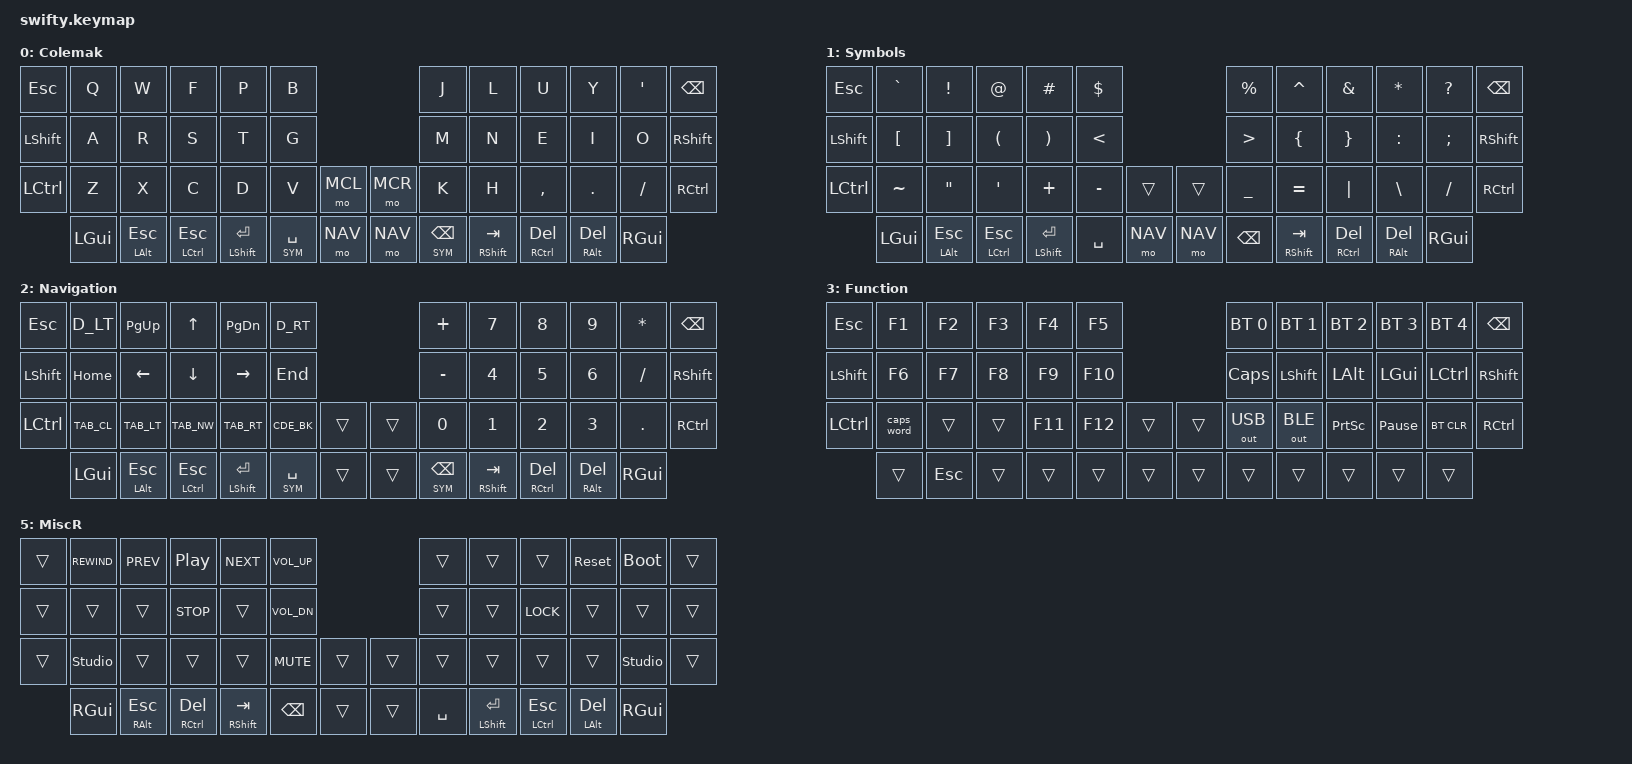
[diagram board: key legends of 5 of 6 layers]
#include <behaviors.dtsi>
#include <dt-bindings/zmk/keys.h>
#include <dt-bindings/zmk/bt.h>
#include <dt-bindings/zmk/outputs.h>
#include <dt-bindings/zmk/rgb.h>
#include <dt-bindings/zmk/rgb_colors.h>
#include <dt-bindings/zmk/hid_indicators.h>

// Layer aliases
#define CMK  0
#define SYM  1
#define NAV  2
#define FUN  3
#define MCL  4
#define MCR  5

// Desktop keycodes
#define D_LT   LC(LA(LEFT))
#define D_RT   LC(LA(RIGHT))

// Browser keycodes
#define TAB_NW LC(T)
#define TAB_RT LC(TAB)
#define TAB_LT LC(LS(TAB))
#define TAB_CL LC(W)

// VS Code keycodes
#define CDE_BK LC(LA(MINUS))
#define CDE_FD LC(LS(MINUS))

&caps_word {
    continue-list = <UNDERSCORE MINUS BSPC DEL N1 N2 N3 N4 N5 N6 N7 N8 N9 N0>;
};


/ {
    behaviors {
          ltr: layer_toggle_right {
               compatible = "zmk,behavior-hold-tap";
               display-name = "LT Right";
               #binding-cells = <2>;
               flavor = "hold-preferred";
               tapping-term-ms = <200>;
               bindings = <&mo>, <&kp>;
          };
          ltl: layer_toggle_left {
               compatible = "zmk,behavior-hold-tap";
               display-name = "LT Left";
               #binding-cells = <2>;
               flavor = "hold-preferred";
               tapping-term-ms = <200>;
               bindings = <&mo>, <&kp>;
          };
    };

    cond_layers {
        compatible = "zmk,conditional-layers";
        // Define FUN layer as tri-state
        navsym {
            if-layers = <NAV SYM>;
            then-layer = <FUN>;
        };
    };

    keymap {
       compatible = "zmk,keymap";
       Colemak_layer {
          display-name = "Colemak";
          bindings = <

// ╭─────────────┬─────────────┬─────────────┬─────────────┬─────────────┬─────────────╮                               ╭─────────────┬─────────────┬─────────────┬─────────────┬─────────────┬─────────────╮
     &kp ESC       &kp Q         &kp W         &kp F         &kp P         &kp B                                         &kp J         &kp L         &kp U         &kp Y         &kp SQT       &kp BSPC
// ├─────────────┼─────────────┼─────────────┼─────────────┼─────────────┼─────────────┤                               ├─────────────┼─────────────┼─────────────┼─────────────┼─────────────┼─────────────┤
     &kp LSHFT     &kp A         &kp R         &kp S         &kp T         &kp G                                         &kp M         &kp N         &kp E         &kp I         &kp O         &kp RSHFT
// ├─────────────┼─────────────┼─────────────┼─────────────┼─────────────┼─────────────┤─────────────╮   ╭─────────────├─────────────┼─────────────┼─────────────┼─────────────┼─────────────┼─────────────┤
     &kp LCTRL     &kp Z         &kp X         &kp C         &kp D         &kp V         &mo MCL           &mo MCR       &kp K         &kp H         &kp COMMA     &kp DOT       &kp SLASH     &kp RCTRL
// ╰─────────────┼─────────────┼─────────────┼─────────────┼─────────────┼─────────────┼─────────────┤   ┼─────────────├─────────────┼─────────────┼─────────────┼─────────────┴─────────────┴─────────────╯
                   &kp LGUI      &mt LALT ESC  &mt LCTRL ESC &mt LSHFT RET &ltr SYM SPACE &mo NAV          &mo NAV       &ltl SYM BSPC &mt RSHFT TAB &mt RCTRL DEL  &mt RALT DEL  &kp RGUI
//               ╰─────────────┴─────────────┴─────────────┴─────────────┴─────────────┴─────────────╯   ╰─────────────┴─────────────┴─────────────┴─────────────┴─────────────┴─────────────╯
        >;

     };
     Symbols_layer { 
          display-name = "Symbols";
          bindings = <
// ╭─────────────┬─────────────┬─────────────┬─────────────┬─────────────┬─────────────╮                               ╭─────────────┬─────────────┬─────────────┬─────────────┬─────────────┬─────────────╮
     &kp ESC       &kp GRAVE     &kp EXCL      &kp AT        &kp HASH      &kp DLLR                                      &kp PRCNT     &kp CARET     &kp AMPS      &kp ASTRK     &kp QMARK     &kp BSPC
// ├─────────────┼─────────────┼─────────────┼─────────────┼─────────────┼─────────────┤                               ├─────────────┼─────────────┼─────────────┼─────────────┼─────────────┼─────────────┤
     &kp LSHFT     &kp LBKT      &kp RBKT      &kp LPAR      &kp RPAR      &kp LT                                        &kp GT        &kp LBRC      &kp RBRC      &kp COLON     &kp SEMI      &kp RSHFT
// ├─────────────┼─────────────┼─────────────┼─────────────┼─────────────┼─────────────┤─────────────╮   ╭─────────────├─────────────┼─────────────┼─────────────┼─────────────┼─────────────┼─────────────┤
     &kp LCTRL     &kp TILDE     &kp DQT       &kp SQT       &kp PLUS      &kp MINUS     &trans            &trans        &kp UNDER     &kp EQUAL     &kp PIPE      &kp BSLH      &kp SLASH     &kp RCTRL
// ╰─────────────┼─────────────┼─────────────┼─────────────┼─────────────┼─────────────┼─────────────┤   ┼─────────────├─────────────┼─────────────┼─────────────┼─────────────┴─────────────┴─────────────╯
                   &kp LGUI      &mt LALT ESC  &mt LCTRL ESC &mt LSHFT RET &kp SPACE      &mo NAV          &mo NAV       &kp BSPC      &mt RSHFT TAB &mt RCTRL DEL &mt RALT DEL  &kp RGUI    
//               ╰─────────────┴─────────────┴─────────────┴─────────────┴─────────────┴─────────────╯   ╰─────────────┴─────────────┴─────────────┴─────────────┴─────────────┴─────────────╯
        >;

     };
     Navigation_layer {
          display-name = "Navigation";
          bindings = <
// ╭─────────────┬─────────────┬─────────────┬─────────────┬─────────────┬─────────────╮                               ╭─────────────┬─────────────┬─────────────┬─────────────┬─────────────┬─────────────╮
     &kp ESC       &kp D_LT      &kp PG_UP     &kp UP        &kp PG_DN     &kp D_RT                                      &kp PLUS      &kp N7        &kp N8        &kp N9        &kp STAR      &kp BSPC
// ├─────────────┼─────────────┼─────────────┼─────────────┼─────────────┼─────────────┤                               ├─────────────┼─────────────┼─────────────┼─────────────┼─────────────┼─────────────┤
     &kp LSHFT     &kp HOME      &kp LEFT      &kp DOWN      &kp RIGHT     &kp END                                       &kp MINUS     &kp N4        &kp N5        &kp N6        &kp SLASH     &kp RSHFT
// ├─────────────┼─────────────┼─────────────┼─────────────┼─────────────┼─────────────┤─────────────╮   ╭─────────────├─────────────┼─────────────┼─────────────┼─────────────┼─────────────┼─────────────┤
     &kp LCTRL     &kp TAB_CL    &kp TAB_LT    &kp TAB_NW    &kp TAB_RT    &kp CDE_BK    &trans             &trans       &kp N0        &kp N1        &kp N2        &kp N3        &kp DOT       &kp RCTRL
// ╰─────────────┼─────────────┼─────────────┼─────────────┼─────────────┼─────────────┼─────────────┤   ┼─────────────├─────────────┼─────────────┼─────────────┼─────────────┴─────────────┴─────────────╯
                   &kp LGUI      &mt LALT ESC  &mt LCTRL ESC &mt LSHFT RET &ltr SYM SPACE &trans           &trans        &ltl SYM BSPC &mt RSHFT TAB &mt RCTRL DEL &mt RALT DEL  &kp RGUI    
//               ╰─────────────┴─────────────┴─────────────┴─────────────┴─────────────┴─────────────╯   ╰─────────────┴─────────────┴─────────────┴─────────────┴─────────────┴─────────────╯
        >;


     };
     Function_layer {
          display-name = "Function";
          bindings = <
// ╭─────────────┬─────────────┬─────────────┬─────────────┬─────────────┬─────────────╮                               ╭─────────────┬─────────────┬─────────────┬─────────────┬─────────────┬─────────────╮
     &kp ESC       &kp F1        &kp F2        &kp F3        &kp F4        &kp F5                                        &bt BT_SEL 0  &bt BT_SEL 1  &bt BT_SEL 2  &bt BT_SEL 3  &bt BT_SEL 4  &kp BSPC  
// ├─────────────┼─────────────┼─────────────┼─────────────┼─────────────┼─────────────┤                               ├─────────────┼─────────────┼─────────────┼─────────────┼─────────────┼─────────────┤
     &kp LSHFT     &kp F6        &kp F7        &kp F8        &kp F9        &kp F10                                       &kp CAPS      &kp LSHIFT    &kp LALT      &kp LGUI      &kp LCTRL     &kp RSHFT
// ├─────────────┼─────────────┼─────────────┼─────────────┼─────────────┼─────────────┤─────────────╮   ╭─────────────├─────────────┼─────────────┼─────────────┼─────────────┼─────────────┼─────────────┤
     &kp LCTRL     &caps_word    &trans        &trans        &kp F11       &kp F12       &trans            &trans        &out OUT_USB  &out OUT_BLE  &kp PSCRN     &kp PAUSE_BREAK &bt BT_CLR  &kp RCTRL
// ╰─────────────┼─────────────┼─────────────┼─────────────┼─────────────┼─────────────┼─────────────┤   ┼─────────────├─────────────┼─────────────┼─────────────┼─────────────┴─────────────┴─────────────╯
                   &trans        &kp ESC       &trans        &trans        &trans        &trans            &trans        &trans        &trans        &trans        &trans        &trans        
//               ╰─────────────┴─────────────┴─────────────┴─────────────┴─────────────┴─────────────╯   ╰─────────────┴─────────────┴─────────────┴─────────────┴─────────────┴─────────────╯
        >;

     };
     MiscL_layer {
          display-name = "MiscL";
          bindings = <
// ╭─────────────┬─────────────┬─────────────┬─────────────┬─────────────┬─────────────╮                               ╭─────────────┬─────────────┬─────────────┬─────────────┬─────────────┬─────────────╮
     &trans        &bootloader   &sys_reset    &trans        &rgb_ug RGB_TOG &rgb_ug RGB_BRI                             &trans        &trans        &trans        &sys_reset    &bootloader   &trans
// ├─────────────┼─────────────┼─────────────┼─────────────┼─────────────┼─────────────┤                               ├─────────────┼─────────────┼─────────────┼─────────────┼─────────────┼─────────────┤
     &trans        &trans        &trans        &kp K_LOCK    &rgb_ug RGB_EFF &rgb_ug RGB_BRD                             &trans        &trans        &kp K_LOCK    &trans        &trans        &trans
// ├─────────────┼─────────────┼─────────────┼─────────────┼─────────────┼─────────────┤─────────────╮   ╭─────────────├─────────────┼─────────────┼─────────────┼─────────────┼─────────────┼─────────────┤
     &trans        &studio_unlock &trans       &trans        &trans        &trans        &trans            &trans         &trans       &trans        &trans        &trans        &studio_unlock &trans
// ╰─────────────┼─────────────┼─────────────┼─────────────┼─────────────┼─────────────┼─────────────┤   ┼─────────────├─────────────┼─────────────┼─────────────┼─────────────┴─────────────┴─────────────╯
                   rans        &trans        &trans        &kp DEL       &kp TAB       &kp BSPC           &kp SPACE     &kp RET      &kp ESC        &trans        &trans        &trans        
                   &kp RGUI      &mt RALT ESC  &mt RCTRL DEL &mt RSHFT TAB &kp BSPC      &trans            &trans        &kp SPACE     &mt LSHFT RET &mt LCTRL ESC  &mt LALT DEL  &kp RGUI
//               ╰─────────────┴─────────────┴─────────────┴─────────────┴─────────────┴─────────────╯   ╰─────────────┴─────────────┴─────────────┴─────────────┴─────────────┴─────────────╯
        >;

     };
     MiscR_layer {
          display-name = "MiscR";
          bindings = <
// ╭─────────────┬─────────────┬─────────────┬─────────────┬─────────────┬─────────────╮                               ╭─────────────┬─────────────┬─────────────┬─────────────┬─────────────┬─────────────╮
     &trans        &kp C_REWIND  &kp C_PREV    &kp C_PP      &kp C_NEXT    &kp C_VOL_UP                                  &trans        &trans        &trans        &sys_reset    &bootloader   &trans
// ├─────────────┼─────────────┼─────────────┼─────────────┼─────────────┼─────────────┤                               ├─────────────┼─────────────┼─────────────┼─────────────┼─────────────┼─────────────┤
     &trans        &trans        &trans        &kp C_STOP    &trans        &kp C_VOL_DN                                  &trans        &trans        &kp K_LOCK    &trans        &trans        &trans
// ├─────────────┼─────────────┼─────────────┼─────────────┼─────────────┼─────────────┤─────────────╮   ╭─────────────├─────────────┼─────────────┼─────────────┼─────────────┼─────────────┼─────────────┤
     &trans        &studio_unlock &trans       &trans        &trans        &kp C_MUTE    &trans            &trans        &trans        &trans        &trans        &trans        &studio_unlock &trans
// ╰─────────────┼─────────────┼─────────────┼─────────────┼─────────────┼─────────────┼─────────────┤   ┼─────────────├─────────────┼─────────────┼──────────────┼─────────────┴─────────────┴─────────────╯
                   &kp RGUI      &mt RALT ESC  &mt RCTRL DEL &mt RSHFT TAB &kp BSPC      &trans            &trans        &kp SPACE     &mt LSHFT RET &mt LCTRL ESC  &mt LALT DEL  &kp RGUI
//               ╰─────────────┴─────────────┴─────────────┴─────────────┴─────────────┴─────────────╯   ╰─────────────┴─────────────┴─────────────┴──────────────┴─────────────┴─────────────╯
        >;
    };
  };

    underglow-layer {
        compatible  = "zmk,underglow-layer";

        lower {
            bindings = <
    &ug ___    &ug WHITE  &ug WHITE  &ug WHITE  &ug WHITE  &ug WHITE                          &ug WHITE  &ug WHITE  &ug WHITE  &ug WHITE  &ug WHITE  &ug ___  
    &ug ___    &ug WHITE  &ug WHITE  &ug WHITE  &ug WHITE  &ug WHITE                          &ug WHITE  &ug WHITE  &ug WHITE  &ug WHITE  &ug WHITE  &ug ___  
    &ug ___    &ug WHITE  &ug WHITE  &ug WHITE  &ug WHITE  &ug WHITE  &ug ___      &ug ___    &ug WHITE  &ug WHITE  &ug WHITE  &ug WHITE  &ug WHITE  &ug ___  
               &ug ___    &ug ___    &ug PINK   &ug TEAL   &ug BLUE   &ug ___      &ug ___    &ug ORANGE  &ug GREEN &ug PURPLE &ug ___    &ug ___  
                >;
            layer-id = <CMK>;
        };
        sym {
            bindings = <
    &ug ___    &ug TEAL   &ug TEAL   &ug TEAL   &ug TEAL   &ug TEAL                           &ug TEAL   &ug TEAL   &ug TEAL   &ug TEAL   &ug TEAL   &ug ___  
    &ug ___    &ug GOLD   &ug GOLD   &ug ORANGE &ug ORANGE &ug YELLOW                         &ug YELLOW &ug PURPLE &ug PURPLE &ug PINK   &ug PINK   &ug ___  
    &ug ___    &ug PINK   &ug TEAL   &ug BLUE   &ug GREEN  &ug RED    &ug ___      &ug ___    &ug RED    &ug WHITE  &ug GOLD   &ug ORANGE &ug YELLOW &ug ___  
               &ug ___    &ug ___    &ug PINK   &ug TEAL   &ug BLUE   &ug ___      &ug ___    &ug WHITE  &ug GREEN  &ug PURPLE &ug ___    &ug ___  
                >;
            layer-id = <SYM>;
        };        
        nav {
            bindings = <
    &ug ___    &ug ORANGE &ug YELLOW &ug BLUE   &ug YELLOW &ug ORANGE                         &ug GREEN  &ug TEAL   &ug TEAL   &ug TEAL   &ug BLUE   &ug ___  
    &ug ___    &ug TEAL   &ug BLUE   &ug BLUE   &ug BLUE   &ug TEAL                           &ug RED    &ug TEAL   &ug TEAL   &ug TEAL   &ug ORANGE &ug ___  
    &ug ___    &ug RED    &ug GOLD   &ug GREEN  &ug GOLD   &ug ___    &ug ___      &ug ___    &ug TEAL   &ug TEAL   &ug TEAL   &ug TEAL   &ug PURPLE &ug ___  
               &ug ___    &ug ___    &ug PINK   &ug TEAL   &ug WHITE  &ug ___      &ug ___    &ug ORANGE &ug GREEN  &ug PURPLE &ug ___    &ug ___  
                >;
            layer-id = <NAV>;
        };      
        fn {
            bindings = <
    &ug ___    &ug TEAL   &ug TEAL   &ug TEAL   &ug TEAL   &ug TEAL                           &ug BLUE   &ug BLUE   &ug BLUE   &ug BLUE   &ug BLUE   &ug ___  
    &ug ___    &ug TEAL   &ug TEAL   &ug TEAL   &ug TEAL   &ug TEAL                           &ug ___    &ug ___    &ug ___    &ug ___    &ug ___    &ug ___  
    &ug ___    &ug RED    &ug ___    &ug ___    &ug TEAL   &ug TEAL   &ug ___      &ug ___    &ug YELLOW &ug TEAL   &ug ___    &ug ___    &ug ___    &ug ___  
               &ug ___    &ug ___    &ug PINK   &ug TEAL   &ug BLUE   &ug ___      &ug ___    &ug ORANGE &ug GREEN  &ug PURPLE &ug ___    &ug ___  
                >;
            layer-id = <FUN>;
        };      
        ml {
            bindings = <
    &ug ___    &ug RED    &ug ORANGE &ug ___    &ug ___    &ug ___                            &ug ___    &ug ___    &ug ___    &ug ORANGE &ug RED    &ug ___  
    &ug ___    &ug ___    &ug ___    &ug PURPLE &ug ___    &ug WHITE                          &ug ___    &ug ___    &ug PURPLE &ug ___    &ug ___    &ug ___  
    &ug ___    &ug BLUE   &ug ___    &ug ___    &ug ___    &ug ___    &ug PINK     &ug ___    &ug ___    &ug ___    &ug ___    &ug ___    &ug BLUE   &ug ___  
               &ug GOLD   &ug GREEN  &ug PURPLE &ug GREEN  &ug ORANGE &ug ___      &ug ___    &ug BLUE   &ug TEAL   &ug PINK   &ug ___    &ug ___  
                >;
            layer-id = <MCL>;
        };      
        mr {
            bindings = <
    &ug ___    &ug RED    &ug ORANGE &ug ___    &ug ___    &ug ___                            &ug ___    &ug ___    &ug ___    &ug ORANGE &ug RED    &ug ___  
    &ug ___    &ug ___    &ug ___    &ug PURPLE &ug ___    &ug WHITE                          &ug WHITE  &ug ___    &ug PURPLE &ug ___    &ug ___    &ug ___  
    &ug ___    &ug BLUE   &ug ___    &ug ___    &ug ___    &ug ___    &ug PINK     &ug ___    &ug ___    &ug ___    &ug ___    &ug ___    &ug BLUE   &ug ___  
               &ug GOLD   &ug GREEN  &ug PURPLE &ug GREEN  &ug ORANGE &ug ___      &ug ___    &ug BLUE   &ug TEAL   &ug PINK   &ug ___    &ug ___  
                >;
            layer-id = <MCR>;
        };
    };
};
